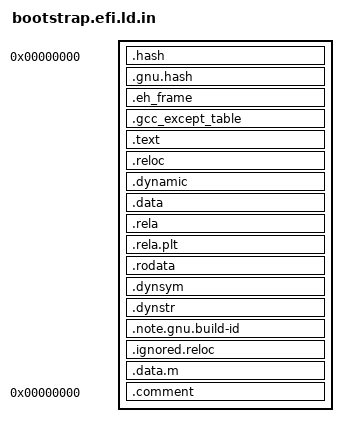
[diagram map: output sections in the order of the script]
/*
 * Copyright (C) 2023-2024 Kernkonzept GmbH.
 * Author(s): Jan Klötzke <jan.kloetzke@kernkonzept.com>
 *            Adam Lackorzynski <adam@l4re.org>
 *
 * Taken from corresponding gnu-efi linkerscript
 */

#include "ldscript.inc"

OUTPUT_FORMAT("elf64-littleaarch64", "elf64-littleaarch64", "elf64-littleaarch64")
OUTPUT_ARCH(aarch64)
ENTRY(_start)
SECTIONS
{
  /*
   * The text section must start at address 0 because it holds the PE/COFF
   * header that must be at the start of the file. In the same vein we also
   * define _start here because there is no real entry point as far as the ELF
   * image is concerned.
   */
  . = 0;
  ImageBase = .;
  /* .hash and/or .gnu.hash MUST come first! */
  .hash : { *(.hash) }
  .gnu.hash : { *(.gnu.hash) }
  . = ALIGN(4096);
  .eh_frame : { *(.eh_frame) }
  .gcc_except_table : { *(.gcc_except_table*) }
  . = ALIGN(4096);
  .text : {
    _stext = .;
    _text = .;
    *(.text.head)
    *(.text)
    *(.text.*)
    *(.gnu.linkonce.t.*)
    *(.plt)
    *(.srodata)
    *(.rodata*)
    . = ALIGN(16);
  }
  _etext = .;
  _text_size = _etext - _text;
  . = ALIGN(65536);
  .reloc :
  {
    KEEP (*(.reloc))
  }
  . = ALIGN(4096);
  .dynamic  : { *(.dynamic) }
  . = ALIGN(4096);
  .data :
  {
   _data = .;
   *(.sdata)
   *(.data)
   *(.data1)
   *(.data.*)
   *(.got.plt)
   *(.got)

    CTORS
    PLATFORMS

   /*
    * Note that these aren't the using the GNU "CONSTRUCTOR" output section
    * command, so they don't start with a size.  Because of p2align and the
    * end/END definitions, and the fact that they're mergeable, they can also
    * have NULLs which aren't guaranteed to be at the end.
    */
/* Leave gnu-efi supplied ctors/dtors except __init_array_start which we
 * also have.
   . = ALIGN(16);
   __init_array_start = .;
   *(SORT(.init_array.*))
   *(.init_array)
   __init_array_end = .;
*/
  . = ALIGN(16);
   __CTOR_LIST__ = .;
   *(SORT(.ctors.*))
   *(.ctors)
   __CTOR_END__ = .;
  . = ALIGN(16);
   __DTOR_LIST__ = .;
   *(SORT(.dtors.*))
   *(.dtors)
   __DTOR_END__ = .;
   . = ALIGN(16);
   __fini_array_start = .;
   *(SORT(.fini_array.*))
   *(.fini_array)
   __fini_array_end = .;

   /* the EFI loader doesn't seem to like a .bss section, so we stick
      it all into .data: */
   . = ALIGN(16);
   _bss = .;
   *(.sbss)
   *(.scommon)
   *(.dynbss)
   *(.bss*)
   *(.bss.*)
   *(COMMON)
   *(.rel.local)
   . = ALIGN(16);

   _bss_end = .;
  }
  _end = .;

  . = ALIGN(4096);
  .rela :
  {
    *(.rela.text*)
    *(.rela.data*)
    *(.rela.got)
    *(.rela.dyn)
    *(.rela.stab)
    *(.rela.init_array*)
    *(.rela.fini_array*)
    *(.rela.ctors*)
    *(.rela.dtors*)
    *(.rela.platformdata)
    *(.rela.l4redeviceuart)
  }
  . = ALIGN(4096);
  .rela.plt : { *(.rela.plt) }
  . = ALIGN(4096);
  .rodata : { *(.rodata*) }
  . = ALIGN(512);

  _edata = .;
  _data_size = _edata - _data;

  . = ALIGN(4096);
  .dynsym   : { *(.dynsym) }
  . = ALIGN(4096);
  .dynstr   : { *(.dynstr) }
  . = ALIGN(4096);
  .note.gnu.build-id : { *(.note.gnu.build-id) }
  .ignored.reloc :
  {
    *(.rela.reloc)
    *(.note.GNU-stack)
  }

  /* Needs to be last so that l4image does not mess up PHDR offsets of other
   * sections. */
  .data.m :
  {
    _module_data_start = .;
    *(.module_data)
    _module_data_end = .;
  }

  .comment 0 : { *(.comment) }
}
